# ATSAMHA1G14AB device description
Architecture: CORTEX-M0PLUS; Family: SAMH; Series: SAMHA1
Registers are 32-bit, read-write, reset 0x0 unless marked. A register's access mark holds for its fields unless they carry their own. Offsets are from the block's base; [hi:lo] are bit positions; {n}, {i} and the like mark numbered series; 'fields as' and 'values as' point back to an identical list; <NAME> marks a mode.

## SERCOM — Serial Communication Interface
Instances: SERCOM{n} {0x42000800+0x400*n} (n=0..5)
Modes: I2CM when SERCOM.I2CM_CTRLA.MODE=5 (I2C Master Mode); I2CS when SERCOM.I2CS_CTRLA.MODE=4 (I2C Slave Mode); SPI when SERCOM.SPI_CTRLA.MODE=2 under mask 6 (SPI Mode); USART when SERCOM.USART_CTRLA.MODE=0 under mask 6 (USART Mode)
0x00 CTRLA <I2CM> — I2CM Control A
  [30] LOWTOUTEN — SCL Low Timeout Enable
  [29:28] INACTOUT — Inactive Time-Out
  [27] SCLSM — SCL Clock Stretch Mode
  [25:24] SPEED — Transfer Speed
  [23] SEXTTOEN — Slave SCL Low Extend Timeout
  [22] MEXTTOEN — Master SCL Low Extend Timeout
  [21:20] SDAHOLD — SDA Hold Time
  [16] PINOUT — Pin Usage
  [7] RUNSTDBY — Run in Standby
  [4:2] MODE — Operating Mode
    0=USART_EXT_CLK (USART mode with external clock); 1=USART_INT_CLK (USART mode with internal clock); 2=SPI_SLAVE (SPI mode with external clock); 3=SPI_MASTER (SPI mode with internal clock); 4=I2C_SLAVE (I2C mode with external clock); 5=I2C_MASTER (I2C mode with internal clock)
  [1] ENABLE
  [0] SWRST — Software Reset
0x04 CTRLB <I2CM> — I2CM Control B
  [18] ACKACT — Acknowledge Action
  [17:16] CMD — Command
  [9] QCEN — Quick Command Enable
  [8] SMEN — Smart Mode Enable
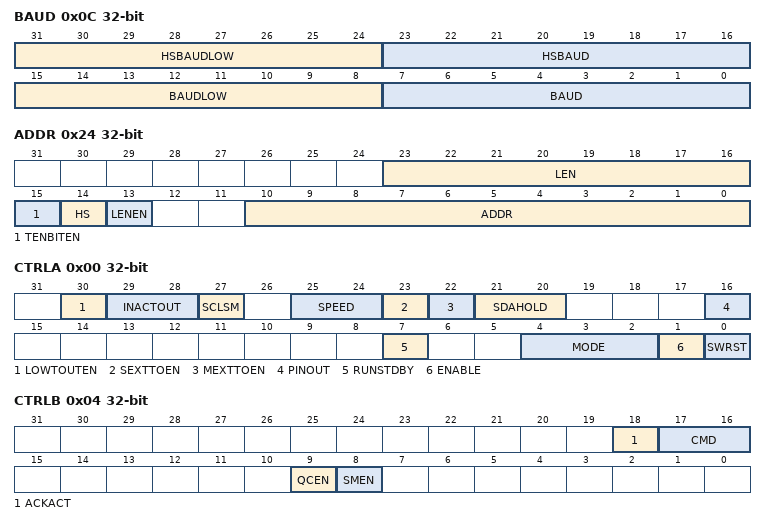
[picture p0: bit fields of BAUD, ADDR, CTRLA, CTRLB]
0x0C BAUD <I2CM> — I2CM Baud Rate
  [31:24] HSBAUDLOW — High Speed Baud Rate Value Low
  [23:16] HSBAUD — High Speed Baud Rate Value
  [15:8] BAUDLOW — Baud Rate Value Low
  [7:0] BAUD — Baud Rate Value
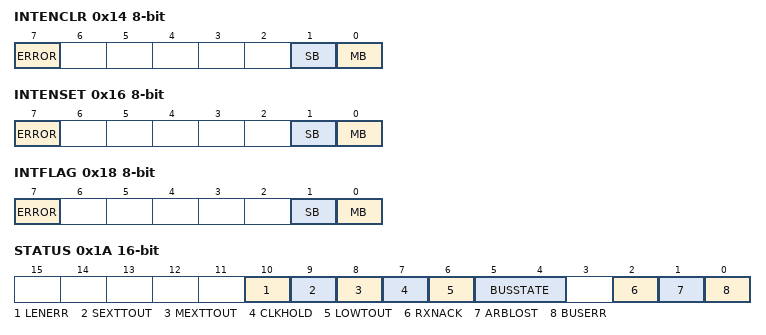
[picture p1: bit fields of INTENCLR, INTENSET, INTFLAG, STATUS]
0x14 INTENCLR <I2CM> 8-bit (atomic clear) — I2CM Interrupt Enable Clear
  [7] ERROR — Combined Error Interrupt Disable
  [1] SB — Slave On Bus Interrupt Disable
  [0] MB — Master On Bus Interrupt Disable
0x16 INTENSET <I2CM> 8-bit (atomic set) — I2CM Interrupt Enable Set
  [7] ERROR — Combined Error Interrupt Enable
  [1] SB — Slave On Bus Interrupt Enable
  [0] MB — Master On Bus Interrupt Enable
0x18 INTFLAG <I2CM> 8-bit (atomic clear) — I2CM Interrupt Flag Status and Clear
  [7] ERROR — Combined Error Interrupt
  [1] SB — Slave On Bus Interrupt
  [0] MB — Master On Bus Interrupt
0x1A STATUS <I2CM> 16-bit — I2CM Status
  [10] LENERR — Length Error
  [9] SEXTTOUT — Slave SCL Low Extend Timeout
  [8] MEXTTOUT — Master SCL Low Extend Timeout
  [7] CLKHOLD — Clock Hold
  [6] LOWTOUT — SCL Low Timeout
  [5:4] BUSSTATE
  [2] RXNACK — Received Not Acknowledge
  [1] ARBLOST — Arbitration Lost
  [0] BUSERR — Bus Error
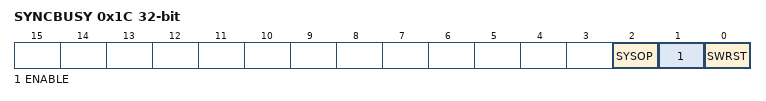
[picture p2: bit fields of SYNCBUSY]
0x1C SYNCBUSY <I2CM> ro — I2CM Synchronization Busy
  [2] SYSOP — System Operation Synchronization Busy
  [1] ENABLE — SERCOM Enable Synchronization Busy
  [0] SWRST — Software Reset Synchronization Busy
0x24 ADDR <I2CM> — I2CM Address
  [23:16] LEN — Length
  [15] TENBITEN — Ten Bit Addressing Enable
  [14] HS — High Speed Mode
  [13] LENEN — Length Enable
  [10:0] ADDR — Address Value
0x28 DATA <I2CM> 8-bit — I2CM Data
  [7:0] DATA — Data Value
0x30 DBGCTRL <I2CM> 8-bit — I2CM Debug Control
  [0] DBGSTOP — Debug Mode
0x00 CTRLA <I2CS> — I2CS Control A
  [30] LOWTOUTEN — SCL Low Timeout Enable
  [27] SCLSM — SCL Clock Stretch Mode
  [25:24] SPEED — Transfer Speed
  [23] SEXTTOEN — Slave SCL Low Extend Timeout
  [21:20] SDAHOLD — SDA Hold Time
  [16] PINOUT — Pin Usage
  [7] RUNSTDBY — Run during Standby
  [4:2] MODE — Operating Mode
    values as CTRLA<I2CM>.MODE
  [1] ENABLE
  [0] SWRST — Software Reset
0x04 CTRLB <I2CS> — I2CS Control B
  [18] ACKACT — Acknowledge Action
  [17:16] CMD — Command
  [15:14] AMODE — Address Mode
  [10] AACKEN — Automatic Address Acknowledge
  [9] GCMD — PMBus Group Command
  [8] SMEN — Smart Mode Enable
0x14 INTENCLR <I2CS> 8-bit (atomic clear) — I2CS Interrupt Enable Clear
  [7] ERROR — Combined Error Interrupt Disable
  [2] DRDY — Data Interrupt Disable
  [1] AMATCH — Address Match Interrupt Disable
  [0] PREC — Stop Received Interrupt Disable
0x16 INTENSET <I2CS> 8-bit (atomic set) — I2CS Interrupt Enable Set
  [7] ERROR — Combined Error Interrupt Enable
  [2] DRDY — Data Interrupt Enable
  [1] AMATCH — Address Match Interrupt Enable
  [0] PREC — Stop Received Interrupt Enable
0x18 INTFLAG <I2CS> 8-bit (atomic clear) — I2CS Interrupt Flag Status and Clear
  [7] ERROR — Combined Error Interrupt
  [2] DRDY — Data Interrupt
  [1] AMATCH — Address Match Interrupt
  [0] PREC — Stop Received Interrupt
0x1A STATUS <I2CS> 16-bit — I2CS Status
  [10] HS — High Speed
  [9] SEXTTOUT — Slave SCL Low Extend Timeout
  [7] CLKHOLD — Clock Hold
  [6] LOWTOUT — SCL Low Timeout
  [4] SR — Repeated Start
  [3] DIR — Read/Write Direction
  [2] RXNACK — Received Not Acknowledge
  [1] COLL — Transmit Collision
  [0] BUSERR — Bus Error
0x1C SYNCBUSY <I2CS> ro — I2CS Synchronization Busy
  [1] ENABLE — SERCOM Enable Synchronization Busy
  [0] SWRST — Software Reset Synchronization Busy
0x24 ADDR <I2CS> — I2CS Address
  [26:17] ADDRMASK — Address Mask
  [15] TENBITEN — Ten Bit Addressing Enable
  [10:1] ADDR — Address Value
  [0] GENCEN — General Call Address Enable
0x28 DATA <I2CS> 8-bit — I2CS Data
  [7:0] DATA — Data Value
0x00 CTRLA <SPI> — SPI Control A
  [30] DORD — Data Order
  [29] CPOL — Clock Polarity
  [28] CPHA — Clock Phase
  [27:24] FORM — Frame Format
  [21:20] DIPO — Data In Pinout
  [17:16] DOPO — Data Out Pinout
  [8] IBON — Immediate Buffer Overflow Notification
  [7] RUNSTDBY — Run during Standby
  [4:2] MODE — Operating Mode
    values as CTRLA<I2CM>.MODE
  [1] ENABLE
  [0] SWRST — Software Reset
0x04 CTRLB <SPI> — SPI Control B
  [17] RXEN — Receiver Enable
  [15:14] AMODE — Address Mode
  [13] MSSEN — Master Slave Select Enable
  [9] SSDE — Slave Select Low Detect Enable
  [6] PLOADEN — Data Preload Enable
  [2:0] CHSIZE — Character Size
0x0C BAUD <SPI> 8-bit — SPI Baud Rate
  [7:0] BAUD — Baud Rate Value
0x14 INTENCLR <SPI> 8-bit (atomic clear) — SPI Interrupt Enable Clear
  [7] ERROR — Combined Error Interrupt Disable
  [3] SSL — Slave Select Low Interrupt Disable
  [2] RXC — Receive Complete Interrupt Disable
  [1] TXC — Transmit Complete Interrupt Disable
  [0] DRE — Data Register Empty Interrupt Disable
0x16 INTENSET <SPI> 8-bit (atomic set) — SPI Interrupt Enable Set
  [7] ERROR — Combined Error Interrupt Enable
  [3] SSL — Slave Select Low Interrupt Enable
  [2] RXC — Receive Complete Interrupt Enable
  [1] TXC — Transmit Complete Interrupt Enable
  [0] DRE — Data Register Empty Interrupt Enable
0x18 INTFLAG <SPI> 8-bit (atomic clear) — SPI Interrupt Flag Status and Clear
  [7] ERROR — Combined Error Interrupt
  [3] SSL — Slave Select Low Interrupt Flag
  [2] RXC — Receive Complete Interrupt
  [1] TXC — Transmit Complete Interrupt
  [0] DRE — Data Register Empty Interrupt
0x1A STATUS <SPI> 16-bit — SPI Status
  [2] BUFOVF — Buffer Overflow
0x1C SYNCBUSY <SPI> ro — SPI Synchronization Busy
  [2] CTRLB — CTRLB Synchronization Busy
  [1] ENABLE — SERCOM Enable Synchronization Busy
  [0] SWRST — Software Reset Synchronization Busy
0x24 ADDR <SPI> — SPI Address
  [23:16] ADDRMASK — Address Mask
  [7:0] ADDR — Address Value
0x28 DATA <SPI> — SPI Data
  [8:0] DATA — Data Value
0x30 DBGCTRL <SPI> 8-bit — SPI Debug Control
  [0] DBGSTOP — Debug Mode
0x00 CTRLA <USART> — USART Control A
  [30] DORD — Data Order
  [29] CPOL — Clock Polarity
  [28] CMODE — Communication Mode
  [27:24] FORM — Frame Format
  [23:22] SAMPA — Sample Adjustment
  [21:20] RXPO — Receive Data Pinout
  [17:16] TXPO — Transmit Data Pinout
  [15:13] SAMPR — Sample
  [8] IBON — Immediate Buffer Overflow Notification
  [7] RUNSTDBY — Run during Standby
  [4:2] MODE — Operating Mode
    values as CTRLA<I2CM>.MODE
  [1] ENABLE
  [0] SWRST — Software Reset
0x04 CTRLB <USART> — USART Control B
  [17] RXEN — Receiver Enable
  [16] TXEN — Transmitter Enable
  [13] PMODE — Parity Mode
  [10] ENC — Encoding Format
  [9] SFDE — Start of Frame Detection Enable
  [8] COLDEN — Collision Detection Enable
  [6] SBMODE — Stop Bit Mode
  [2:0] CHSIZE — Character Size
0x0C BAUD <USART> 16-bit — USART Baud Rate
  [15:0] BAUD <DEFAULT USARTFP> — Baud Rate Value
  [15:13] FP <FRAC FRACFP> — Fractional Part
  [12:0] BAUD <FRAC FRACFP> — Baud Rate Value
0x0E RXPL <USART> 8-bit — USART Receive Pulse Length
  [7:0] RXPL — Receive Pulse Length
0x14 INTENCLR <USART> 8-bit (atomic clear) — USART Interrupt Enable Clear
  [7] ERROR — Combined Error Interrupt Disable
  [5] RXBRK — Break Received Interrupt Disable
  [4] CTSIC — Clear To Send Input Change Interrupt Disable
  [3] RXS — Receive Start Interrupt Disable
  [2] RXC — Receive Complete Interrupt Disable
  [1] TXC — Transmit Complete Interrupt Disable
  [0] DRE — Data Register Empty Interrupt Disable
0x16 INTENSET <USART> 8-bit (atomic set) — USART Interrupt Enable Set
  [7] ERROR — Combined Error Interrupt Enable
  [5] RXBRK — Break Received Interrupt Enable
  [4] CTSIC — Clear To Send Input Change Interrupt Enable
  [3] RXS — Receive Start Interrupt Enable
  [2] RXC — Receive Complete Interrupt Enable
  [1] TXC — Transmit Complete Interrupt Enable
  [0] DRE — Data Register Empty Interrupt Enable
0x18 INTFLAG <USART> 8-bit (atomic clear) — USART Interrupt Flag Status and Clear
  [7] ERROR — Combined Error Interrupt
  [5] RXBRK — Break Received Interrupt
  [4] CTSIC — Clear To Send Input Change Interrupt
  [3] RXS — Receive Start Interrupt
  [2] RXC — Receive Complete Interrupt
  [1] TXC — Transmit Complete Interrupt
  [0] DRE — Data Register Empty Interrupt
0x1A STATUS <USART> 16-bit — USART Status
  [5] COLL — Collision Detected
  [4] ISF — Inconsistent Sync Field
  [3] CTS — Clear To Send
  [2] BUFOVF — Buffer Overflow
  [1] FERR — Frame Error
  [0] PERR — Parity Error
0x1C SYNCBUSY <USART> ro — USART Synchronization Busy
  fields as SYNCBUSY<SPI>
0x28 DATA <USART> 16-bit — USART Data
  [8:0] DATA — Data Value
0x30 DBGCTRL <USART> 8-bit — USART Debug Control
  [0] DBGSTOP — Debug Mode

## Notices in the file
Copyright (c) 2018 Microchip Technology Inc.
SPDX-License-Identifier: Apache-2.0
Licensed under the Apache License, Version 2.0 (the "License");
you may not use this file except in compliance with the License.
You may obtain a copy of the License at
http://www.apache.org/licenses/LICENSE-2.0
Unless required by applicable law or agreed to in writing, software
distributed under the License is distributed on an "AS IS" BASIS,
WITHOUT WARRANTIES OR CONDITIONS OF ANY KIND, either express or implied.
See the License for the specific language governing permissions and
limitations under the License.
